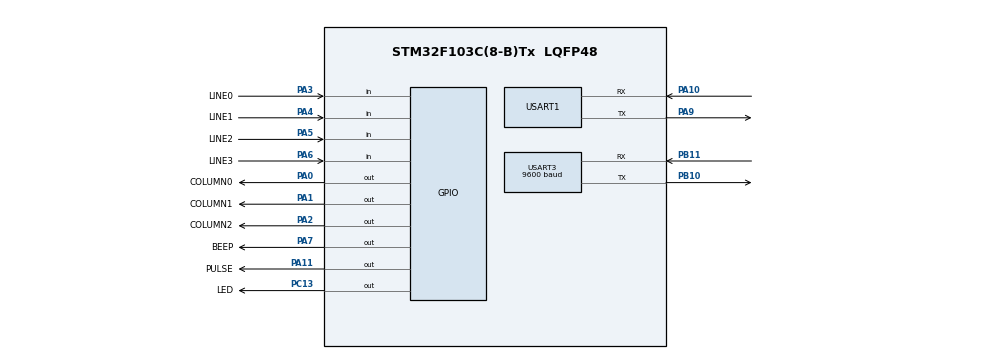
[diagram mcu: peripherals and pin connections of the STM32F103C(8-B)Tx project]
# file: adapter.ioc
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Mcu.Family=STM32F1
Mcu.Name=STM32F103C(8-B)Tx
Mcu.Package=LQFP48
NVIC.PriorityGroup=NVIC_PRIORITYGROUP_4
NVIC.RCC_IRQn=true\:0\:0\:false\:true\:true\:3\:true
NVIC.TIM3_IRQn=true\:0\:0\:false\:true\:true\:4\:true
NVIC.USART1_IRQn=true\:0\:0\:false\:true\:true\:2\:true
NVIC.USART3_IRQn=true\:0\:0\:false\:true\:true\:1\:true
PA0-WKUP.GPIO_Label=COLUMN0
PA0-WKUP.Signal=GPIO_Output
PA1.GPIO_Label=COLUMN1
PA1.Signal=GPIO_Output
PA10.Mode=Asynchronous
PA10.Signal=USART1_RX
PA11.GPIO_Label=PULSE
PA11.GPIO_Speed=GPIO_SPEED_FREQ_HIGH
PA11.PinState=GPIO_PIN_SET
PA11.Signal=GPIO_Output
PA13.Mode=Serial_Wire
PA13.Signal=SYS_JTMS-SWDIO
PA14.Mode=Serial_Wire
PA14.Signal=SYS_JTCK-SWCLK
PA2.GPIO_Label=COLUMN2
PA2.Signal=GPIO_Output
PA3.GPIO_Label=LINE0
PA3.GPIO_PuPd=GPIO_PULLDOWN
PA3.Signal=GPIO_Input
PA4.GPIO_Label=LINE1
PA4.GPIO_PuPd=GPIO_PULLDOWN
PA4.Signal=GPIO_Input
PA5.GPIO_Label=LINE2
PA5.GPIO_PuPd=GPIO_PULLDOWN
PA5.Signal=GPIO_Input
PA6.GPIO_Label=LINE3
PA6.GPIO_PuPd=GPIO_PULLDOWN
PA6.Signal=GPIO_Input
PA7.GPIO_Label=BEEP
PA7.GPIO_PuPd=GPIO_PULLDOWN
PA7.Signal=GPIO_Output
PA9.Mode=Asynchronous
PA9.Signal=USART1_TX
PB10.Mode=Asynchronous
PB10.Signal=USART3_TX
PB11.Mode=Asynchronous
PB11.Signal=USART3_RX
PC13-TAMPER-RTC.GPIO_Label=LED
PC13-TAMPER-RTC.GPIO_PuPd=GPIO_PULLDOWN
PC13-TAMPER-RTC.Signal=GPIO_Output
PD0-OSC_IN.Mode=HSE-External-Oscillator
PD0-OSC_IN.Signal=RCC_OSC_IN
PD1-OSC_OUT.Mode=HSE-External-Oscillator
PD1-OSC_OUT.Signal=RCC_OSC_OUT
ProjectManager.HeapSize=0x200
ProjectManager.StackSize=0x400
ProjectManager.TargetToolchain=MDK-ARM V5
RCC.AHBFreq_Value=72000000
RCC.APB1CLKDivider=RCC_HCLK_DIV2
RCC.APB1Freq_Value=36000000
RCC.APB1TimFreq_Value=72000000
RCC.APB2Freq_Value=72000000
RCC.APB2TimFreq_Value=72000000
RCC.HCLKFreq_Value=72000000
RCC.PLLMUL=RCC_PLL_MUL9
RCC.PLLSourceVirtual=RCC_PLLSOURCE_HSE
RCC.SYSCLKFreq_VALUE=72000000
RCC.SYSCLKSource=RCC_SYSCLKSOURCE_PLLCLK
RCC.USBFreq_Value=72000000
TIM3.Period=500-1
TIM3.Prescaler=36000-1
TIM3.TIM_MasterOutputTrigger=TIM_TRGO_UPDATE
USART1.VirtualMode=VM_ASYNC
USART3.BaudRate=9600
USART3.VirtualMode=VM_ASYNC
VP_TIM3_VS_ClockSourceINT.Mode=Internal
board=custom

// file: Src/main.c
/* USER CODE BEGIN Header */
/**
  ******************************************************************************
  * @file           : main.c
  * @brief          : Main program body
  ******************************************************************************
  ** This notice applies to any and all portions of this file
  * that are not between comment pairs USER CODE BEGIN and
  * USER CODE END. Other portions of this file, whether
  * inserted by the user or by software development tools
  * are owned by their respective copyright owners.
  *
  * COPYRIGHT(c) 2020 STMicroelectronics
  *
  * Redistribution and use in source and binary forms, with or without modification,
  * are permitted provided that the following conditions are met:
  *   1. Redistributions of source code must retain the above copyright notice,
  *      this list of conditions and the following disclaimer.
  *   2. Redistributions in binary form must reproduce the above copyright notice,
  *      this list of conditions and the following disclaimer in the documentation
  *      and/or other materials provided with the distribution.
  *   3. Neither the name of STMicroelectronics nor the names of its contributors
  *      may be used to endorse or promote products derived from this software
  *      without specific prior written permission.
  *
  * THIS SOFTWARE IS PROVIDED BY THE COPYRIGHT HOLDERS AND CONTRIBUTORS "AS IS"
  * AND ANY EXPRESS OR IMPLIED WARRANTIES, INCLUDING, BUT NOT LIMITED TO, THE
  * IMPLIED WARRANTIES OF MERCHANTABILITY AND FITNESS FOR A PARTICULAR PURPOSE ARE
  * DISCLAIMED. IN NO EVENT SHALL THE COPYRIGHT HOLDER OR CONTRIBUTORS BE LIABLE
  * FOR ANY DIRECT, INDIRECT, INCIDENTAL, SPECIAL, EXEMPLARY, OR CONSEQUENTIAL
  * DAMAGES (INCLUDING, BUT NOT LIMITED TO, PROCUREMENT OF SUBSTITUTE GOODS OR
  * SERVICES; LOSS OF USE, DATA, OR PROFITS; OR BUSINESS INTERRUPTION) HOWEVER
  * CAUSED AND ON ANY THEORY OF LIABILITY, WHETHER IN CONTRACT, STRICT LIABILITY,
  * OR TORT (INCLUDING NEGLIGENCE OR OTHERWISE) ARISING IN ANY WAY OUT OF THE USE
  * OF THIS SOFTWARE, EVEN IF ADVISED OF THE POSSIBILITY OF SUCH DAMAGE.
  *
  ******************************************************************************
  */
/* USER CODE END Header */

#include "main.h"
#include "tim.h"
#include "usart.h"
#include "gpio.h"

/* USER CODE BEGIN Includes */
#include "3x4keyboard.h"
#include "bposLight.h"
/* USER CODE END Includes */

/* USER CODE BEGIN PV */
extern uint32_t sysTick;
/* USER CODE END PV */

void SystemClock_Config(void);
static void MX_NVIC_Init(void);

int main(void)
{

  /* MCU Configuration--------------------------------------------------------*/

  /* Reset of all peripherals, Initializes the Flash interface and the Systick. */

  LL_APB2_GRP1_EnableClock(LL_APB2_GRP1_PERIPH_AFIO);
  LL_APB1_GRP1_EnableClock(LL_APB1_GRP1_PERIPH_PWR);

  NVIC_SetPriorityGrouping(NVIC_PRIORITYGROUP_4);

  /* System interrupt init*/

  /* Peripheral interrupt init*/

  /**NOJTAG: JTAG-DP Disabled and SW-DP Enabled
  */
  LL_GPIO_AF_Remap_SWJ_NOJTAG();

  /* Configure the system clock */
  SystemClock_Config();

  /* Initialize all configured peripherals */
  MX_GPIO_Init();
  MX_USART1_UART_Init();
  MX_USART3_UART_Init();
  MX_TIM3_Init();

  /* Initialize interrupts */
  MX_NVIC_Init();
  /* USER CODE BEGIN 2 */
	/***************************************************************/
	LL_SYSTICK_EnableIT();					//прерывание по systic
	LL_USART_EnableIT_IDLE(USART1);	//прерывание по окончанию приема
	LL_USART_EnableIT_RXNE(USART1);	//прерывание по получению байта
	LL_TIM_EnableIT_UPDATE(TIM3);
	LL_TIM_EnableCounter(TIM3);
	/***************************************************************/
  /* USER CODE END 2 */

  /* Infinite loop */
  while (1)
  {

    /* USER CODE BEGIN 3 */

		//читаем клавиатуру
		ChangeColumn ();

		//проверяем получены ли данные
		//если да, парсим и выставляем нужный флаг ответа
		BPOS_cmd_handler();

		//отвечаем согласно флагу, выставляем флаг отпуска товара
		BPOS_cmd_resp();

		//проверяем флаг отпуска, цену пульса и считаем количество пульсов
		//SalePulse();

		//Pulse();

  }
  /* USER CODE END 3 */
}

void SystemClock_Config(void)
{
  LL_FLASH_SetLatency(LL_FLASH_LATENCY_2);

   if(LL_FLASH_GetLatency() != LL_FLASH_LATENCY_2)
  {
    Error_Handler();
  }
  LL_RCC_HSE_Enable();

   /* Wait till HSE is ready */
  while(LL_RCC_HSE_IsReady() != 1)
  {

  }
  LL_RCC_PLL_ConfigDomain_SYS(LL_RCC_PLLSOURCE_HSE_DIV_1, LL_RCC_PLL_MUL_9);
  LL_RCC_PLL_Enable();

   /* Wait till PLL is ready */
  while(LL_RCC_PLL_IsReady() != 1)
  {

  }
  LL_RCC_SetAHBPrescaler(LL_RCC_SYSCLK_DIV_1);
  LL_RCC_SetAPB1Prescaler(LL_RCC_APB1_DIV_2);
  LL_RCC_SetAPB2Prescaler(LL_RCC_APB2_DIV_1);
  LL_RCC_SetSysClkSource(LL_RCC_SYS_CLKSOURCE_PLL);

   /* Wait till System clock is ready */
  while(LL_RCC_GetSysClkSource() != LL_RCC_SYS_CLKSOURCE_STATUS_PLL)
  {

  }
  LL_Init1msTick(72000000);
  LL_SYSTICK_SetClkSource(LL_SYSTICK_CLKSOURCE_HCLK);
  LL_SetSystemCoreClock(72000000);
}

/**
  * @brief NVIC Configuration.
  * @retval None
  */
static void MX_NVIC_Init(void)
{
  /* USART3_IRQn interrupt configuration */
  NVIC_SetPriority(USART3_IRQn, NVIC_EncodePriority(NVIC_GetPriorityGrouping(),0, 0));
  NVIC_EnableIRQ(USART3_IRQn);
  /* USART1_IRQn interrupt configuration */
  NVIC_SetPriority(USART1_IRQn, NVIC_EncodePriority(NVIC_GetPriorityGrouping(),0, 0));
  NVIC_EnableIRQ(USART1_IRQn);
  /* RCC_IRQn interrupt configuration */
  NVIC_SetPriority(RCC_IRQn, NVIC_EncodePriority(NVIC_GetPriorityGrouping(),0, 0));
  NVIC_EnableIRQ(RCC_IRQn);
  /* TIM3_IRQn interrupt configuration */
  NVIC_SetPriority(TIM3_IRQn, NVIC_EncodePriority(NVIC_GetPriorityGrouping(),0, 0));
  NVIC_EnableIRQ(TIM3_IRQn);
}

void Error_Handler(void)
{
}

/************************ (C) COPYRIGHT STMicroelectronics *****END OF FILE****/
